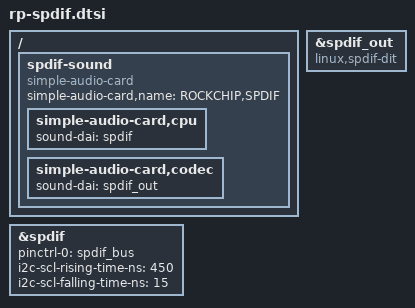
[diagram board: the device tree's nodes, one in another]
/{
    spdif-sound {
        status = "okay";
        compatible = "simple-audio-card";
        simple-audio-card,name = "ROCKCHIP,SPDIF";
        simple-audio-card,cpu {
            sound-dai = <&spdif>;
        };
        simple-audio-card,codec {
            sound-dai = <&spdif_out>;
        };
    };
};

&spdif {
    status = "okay";
    pinctrl-0 = <&spdif_bus>; //<4 RK_PC5 1 &pcfg_pull_none>;
    i2c-scl-rising-time-ns = <450>;
    i2c-scl-falling-time-ns = <15>;
    #sound-dai-cells = <0>;
};

&spdif_out {
    status = "okay";
    compatible = "linux,spdif-dit";
    #sound-dai-cells = <0>;
};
